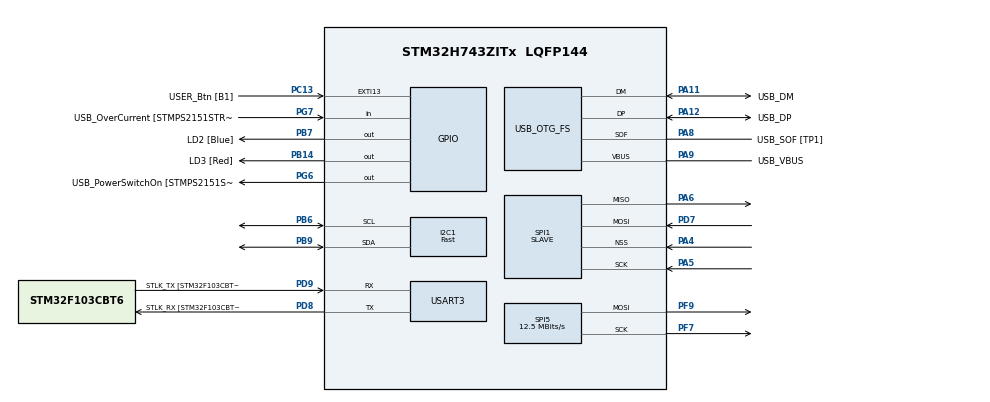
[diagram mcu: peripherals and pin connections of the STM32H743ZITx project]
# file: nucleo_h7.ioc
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FREERTOS.Tasks01=defaultTask,0,128,StartDefaultTask,Default,NULL
I2C1.I2C_Speed_Mode=I2C_Fast
I2C1.Timing=0x009034B6
Mcu.Family=STM32H7
Mcu.Name=STM32H743ZITx
Mcu.Package=LQFP144
NVIC.PriorityGroup=NVIC_PRIORITYGROUP_4
NVIC.SPI1_IRQn=true\:5\:0\:false\:false\:true\:true\:true
NVIC.TIM1_UP_IRQn=true\:0\:0\:false\:false\:true\:false\:false
NVIC.TimeBase=TIM1_UP_IRQn
NVIC.TimeBaseIP=TIM1
PA1.GPIO_Label=RMII_REF_CLK
PA1.Signal=ETH_REF_CLK
PA10.GPIO_Label=USB_ID
PA10.Signal=USB_OTG_FS_ID
PA11.GPIO_Label=USB_DM
PA11.Mode=Device_Only
PA11.Signal=USB_OTG_FS_DM
PA12.GPIO_Label=USB_DP
PA12.Mode=Device_Only
PA12.Signal=USB_OTG_FS_DP
PA13\ (JTMS/SWDIO).GPIO_Label=TMS
PA13\ (JTMS/SWDIO).Mode=Serial_Wire
PA13\ (JTMS/SWDIO).Signal=SYS_JTMS-SWDIO
PA14\ (JTCK/SWCLK).GPIO_Label=TCK
PA14\ (JTCK/SWCLK).Mode=Serial_Wire
PA14\ (JTCK/SWCLK).Signal=SYS_JTCK-SWCLK
PA2.GPIO_Label=RMII_MDIO
PA2.Signal=ETH_MDIO
PA4.GPIO_Speed=GPIO_SPEED_FREQ_VERY_HIGH
PA4.Mode=NSS_Signal_Hard_Input
PA4.Signal=SPI1_NSS
PA5.GPIO_Speed=GPIO_SPEED_FREQ_VERY_HIGH
PA5.Mode=Full_Duplex_Slave
PA5.Signal=SPI1_SCK
PA6.GPIO_Speed=GPIO_SPEED_FREQ_VERY_HIGH
PA6.Mode=Full_Duplex_Slave
PA6.Signal=SPI1_MISO
PA7.GPIO_Label=RMII_CRS_DV
PA7.Signal=ETH_CRS_DV
PA8.GPIO_Label=USB_SOF [TP1]
PA8.Mode=Activate_SOF_FS
PA8.Signal=USB_OTG_FS_SOF
PA9.GPIO_Label=USB_VBUS
PA9.Mode=Activate_VBUS
PA9.Signal=USB_OTG_FS_VBUS
PB13.GPIO_Label=RMII_TXD1
PB13.Signal=ETH_TXD1
PB14.GPIO_Label=LD3 [Red]
PB14.Signal=GPIO_Output
PB3\ (JTDO/TRACESWO).GPIO_Label=SWO
PB3\ (JTDO/TRACESWO).Signal=SYS_JTDO-SWO
PB6.GPIO_FM6=SYSCFG_PMCR_I2C_PB6_FMP
PB6.Mode=I2C
PB6.Signal=I2C1_SCL
PB7.GPIO_Label=LD2 [Blue]
PB7.Signal=GPIO_Output
PB9.GPIO_FM9=SYSCFG_PMCR_I2C_PB9_FMP
PB9.Mode=I2C
PB9.Signal=I2C1_SDA
PC1.GPIO_Label=RMII_MDC
PC1.Signal=ETH_MDC
PC13.GPIO_Label=USER_Btn [B1]
PC13.Signal=GPXTI13
PC14-OSC32_IN\ (OSC32_IN).Mode=LSE-External-Oscillator
PC14-OSC32_IN\ (OSC32_IN).Signal=RCC_OSC32_IN
PC15-OSC32_OUT\ (OSC32_OUT).Mode=LSE-External-Oscillator
PC15-OSC32_OUT\ (OSC32_OUT).Signal=RCC_OSC32_OUT
PC4.GPIO_Label=RMII_RXD0
PC4.Signal=ETH_RXD0
PC5.GPIO_Label=RMII_RXD1
PC5.Signal=ETH_RXD1
PD7.GPIO_Speed=GPIO_SPEED_FREQ_VERY_HIGH
PD7.Mode=Full_Duplex_Slave
PD7.Signal=SPI1_MOSI
PD8.GPIO_Label=STLK_RX [STM32F103CBT6_PA3]
PD8.Mode=Asynchronous
PD8.Signal=USART3_TX
PD9.GPIO_Label=STLK_TX [STM32F103CBT6_PA2]
PD9.Mode=Asynchronous
PD9.Signal=USART3_RX
PF7.Mode=TX_Only_Simplex_Unidirect_Master
PF7.Signal=SPI5_SCK
PF9.Mode=TX_Only_Simplex_Unidirect_Master
PF9.Signal=SPI5_MOSI
PG11.GPIO_Label=RMII_TX_EN
PG11.Signal=ETH_TX_EN
PG13.GPIO_Label=RMII_TXD0
PG13.Signal=ETH_TXD0
PG6.GPIO_Label=USB_PowerSwitchOn [STMPS2151STR_EN]
PG6.Signal=GPIO_Output
PG7.GPIO_Label=USB_OverCurrent [STMPS2151STR_FAULT]
PG7.Signal=GPIO_Input
PH0-OSC_IN\ (PH0).GPIO_Label=MCO
PH0-OSC_IN\ (PH0).Mode=HSE-External-Clock-Source
PH0-OSC_IN\ (PH0).Signal=RCC_OSC_IN
PH1-OSC_OUT\ (PH1).Mode=HSE-External-Clock-Source
PH1-OSC_OUT\ (PH1).Signal=RCC_OSC_OUT
ProjectManager.HeapSize=0x200
ProjectManager.StackSize=0x400
ProjectManager.TargetToolchain=Makefile
RCC.48MHZClocksFreq_Value=24000000
RCC.ADCFreq_Value=4687500
RCC.AHBFreq_Value=216000000
RCC.APB1CLKDivider=RCC_HCLK_DIV4
RCC.APB1Freq_Value=100000000
RCC.APB1TimFreq_Value=108000000
RCC.APB2CLKDivider=RCC_HCLK_DIV2
RCC.APB2Freq_Value=100000000
RCC.APB2TimFreq_Value=216000000
RCC.APB3Freq_Value=100000000
RCC.APB4Freq_Value=100000000
RCC.CortexFreq_Value=400000000
RCC.DIVM1=1
RCC.DIVM2=8
RCC.DIVN1=100
RCC.DIVN2=150
RCC.DIVP2=32
RCC.DIVQ1=4
RCC.HCLKFreq_Value=100000000
RCC.HPRE=RCC_HCLK_DIV4
RCC.HSE_VALUE=8000000
RCC.HSI_VALUE=64000000
RCC.PLLM=25
RCC.PLLMUL=RCC_PLL_MUL9
RCC.PLLN=432
RCC.PLLQ=9
RCC.PLLSourceVirtual=RCC_PLLSOURCE_HSE
RCC.PRESCALERUSB=RCC_USBCLKSOURCE_PLL_DIV1_5
RCC.SPI123CLockSelection=RCC_SPI123CLKSOURCE_PLL2
RCC.SYSCLKFreq_VALUE=400000000
RCC.SYSCLKSource=RCC_SYSCLKSOURCE_PLLCLK
RCC.SYSCLKSourceVirtual=RCC_SYSCLKSOURCE_PLLCLK
RCC.USBCLockSelection=RCC_USBCLKSOURCE_HSI48
RCC.USBFreq_Value=48000000
RCC.VCOOutputFreq_Value=432000000
SPI1.DataSize=SPI_DATASIZE_8BIT
SPI1.Direction=SPI_DIRECTION_2LINES
SPI1.Mode=SPI_MODE_SLAVE
SPI1.VirtualNSS=VM_NSSHARD
SPI1.VirtualType=VM_SLAVE
SPI5.BaudRatePrescaler=SPI_BAUDRATEPRESCALER_8
SPI5.CalculateBaudRate=12.5 MBits/s
SPI5.DataSize=SPI_DATASIZE_8BIT
SPI5.Direction=SPI_DIRECTION_2LINES_TXONLY
SPI5.Mode=SPI_MODE_MASTER
SPI5.VirtualType=VM_MASTER
USART3.VirtualMode-Asynchronous=VM_ASYNC
USB_OTG_FS.VirtualMode=Device_Only
VP_FREERTOS_VS_ENABLE.Mode=Enabled
VP_SYS_VS_tim1.Mode=TIM1
board=NUCLEO-H743ZI

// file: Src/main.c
/* USER CODE BEGIN Header */
/**
  ******************************************************************************
  * @file           : main.c
  * @brief          : Main program body
  ******************************************************************************
  * This notice applies to any and all portions of this file
  * that are not between comment pairs USER CODE BEGIN and
  * USER CODE END. Other portions of this file, whether
  * inserted by the user or by software development tools
  * are owned by their respective copyright owners.
  *
  * Copyright (c) 2019 STMicroelectronics International N.V.
  * All rights reserved.
  *
  * Redistribution and use in source and binary forms, with or without
  * modification, are permitted, provided that the following conditions are met:
  *
  * 1. Redistribution of source code must retain the above copyright notice,
  *    this list of conditions and the following disclaimer.
  * 2. Redistributions in binary form must reproduce the above copyright notice,
  *    this list of conditions and the following disclaimer in the documentation
  *    and/or other materials provided with the distribution.
  * 3. Neither the name of STMicroelectronics nor the names of other
  *    contributors to this software may be used to endorse or promote products
  *    derived from this software without specific written permission.
  * 4. This software, including modifications and/or derivative works of this
  *    software, must execute solely and exclusively on microcontroller or
  *    microprocessor devices manufactured by or for STMicroelectronics.
  * 5. Redistribution and use of this software other than as permitted under
  *    this license is void and will automatically terminate your rights under
  *    this license.
  *
  * THIS SOFTWARE IS PROVIDED BY STMICROELECTRONICS AND CONTRIBUTORS "AS IS"
  * AND ANY EXPRESS, IMPLIED OR STATUTORY WARRANTIES, INCLUDING, BUT NOT
  * LIMITED TO, THE IMPLIED WARRANTIES OF MERCHANTABILITY, FITNESS FOR A
  * PARTICULAR PURPOSE AND NON-INFRINGEMENT OF THIRD PARTY INTELLECTUAL PROPERTY
  * RIGHTS ARE DISCLAIMED TO THE FULLEST EXTENT PERMITTED BY LAW. IN NO EVENT
  * SHALL STMICROELECTRONICS OR CONTRIBUTORS BE LIABLE FOR ANY DIRECT, INDIRECT,
  * INCIDENTAL, SPECIAL, EXEMPLARY, OR CONSEQUENTIAL DAMAGES (INCLUDING, BUT NOT
  * LIMITED TO, PROCUREMENT OF SUBSTITUTE GOODS OR SERVICES; LOSS OF USE, DATA,
  * OR PROFITS; OR BUSINESS INTERRUPTION) HOWEVER CAUSED AND ON ANY THEORY OF
  * LIABILITY, WHETHER IN CONTRACT, STRICT LIABILITY, OR TORT (INCLUDING
  * NEGLIGENCE OR OTHERWISE) ARISING IN ANY WAY OUT OF THE USE OF THIS SOFTWARE,
  * EVEN IF ADVISED OF THE POSSIBILITY OF SUCH DAMAGE.
  *
  ******************************************************************************
  */
/* USER CODE END Header */

#include "main.h"
#include "cmsis_os.h"
#include "i2c.h"
#include "spi.h"
#include "usart.h"
#include "usb_otg.h"
#include "gpio.h"

/* USER CODE BEGIN Includes */
#include "main_task.h"
#include "SEGGER_RTT.h"

/* USER CODE END Includes */

/* USER CODE BEGIN PV */
osThreadId main_task_handle;

/* USER CODE END PV */

void SystemClock_Config(void);
void MX_FREERTOS_Init(void);

int main(void)
{

  /* MCU Configuration--------------------------------------------------------*/

  /* Reset of all peripherals, Initializes the Flash interface and the Systick. */
  HAL_Init();

  /* Configure the system clock */
  SystemClock_Config();

  /* Initialize all configured peripherals */
  MX_GPIO_Init();
  MX_USART3_UART_Init();
  MX_USB_OTG_FS_PCD_Init();
  MX_I2C1_Init();
  MX_SPI1_Init();
  MX_SPI5_Init();
  /* USER CODE BEGIN 2 */
  SEGGER_RTT_printf(0,"error hal state i2c %x\r\n",HAL_I2C_GetState(&hi2c1));
  osThreadDef(main_thread, main_task, osPriorityNormal, 0, 1024);
  main_task_handle = osThreadCreate(osThread(main_thread), NULL);

  /* USER CODE END 2 */

  /* Start scheduler */
  osKernelStart();

  /* We should never get here as control is now taken by the scheduler */

  /* Infinite loop */
  while (1)
  {

  }
}

void SystemClock_Config(void)
{
  RCC_OscInitTypeDef RCC_OscInitStruct = {0};
  RCC_ClkInitTypeDef RCC_ClkInitStruct = {0};
  RCC_PeriphCLKInitTypeDef PeriphClkInitStruct = {0};

  /**Supply configuration update enable
  */
  MODIFY_REG(PWR->CR3, PWR_CR3_SCUEN, 0);
  /**Configure the main internal regulator output voltage
  */
  __HAL_PWR_VOLTAGESCALING_CONFIG(PWR_REGULATOR_VOLTAGE_SCALE1);

  while ((PWR->D3CR & (PWR_D3CR_VOSRDY)) != PWR_D3CR_VOSRDY)
  {

  }
  /**Macro to configure the PLL clock source
  */
  __HAL_RCC_PLL_PLLSOURCE_CONFIG(RCC_PLLSOURCE_HSE);
  /**Initializes the CPU, AHB and APB busses clocks
  */
  RCC_OscInitStruct.OscillatorType = RCC_OSCILLATORTYPE_HSI48|RCC_OSCILLATORTYPE_HSE;
  RCC_OscInitStruct.HSEState = RCC_HSE_BYPASS;
  RCC_OscInitStruct.HSI48State = RCC_HSI48_ON;
  RCC_OscInitStruct.PLL.PLLState = RCC_PLL_ON;
  RCC_OscInitStruct.PLL.PLLSource = RCC_PLLSOURCE_HSE;
  RCC_OscInitStruct.PLL.PLLM = 1;
  RCC_OscInitStruct.PLL.PLLN = 100;
  RCC_OscInitStruct.PLL.PLLP = 2;
  RCC_OscInitStruct.PLL.PLLQ = 4;
  RCC_OscInitStruct.PLL.PLLR = 2;
  RCC_OscInitStruct.PLL.PLLRGE = RCC_PLL1VCIRANGE_3;
  RCC_OscInitStruct.PLL.PLLVCOSEL = RCC_PLL1VCOWIDE;
  RCC_OscInitStruct.PLL.PLLFRACN = 0;
  if (HAL_RCC_OscConfig(&RCC_OscInitStruct) != HAL_OK)
  {
    Error_Handler();
  }
  /**Initializes the CPU, AHB and APB busses clocks
  */
  RCC_ClkInitStruct.ClockType = RCC_CLOCKTYPE_HCLK|RCC_CLOCKTYPE_SYSCLK
                              |RCC_CLOCKTYPE_PCLK1|RCC_CLOCKTYPE_PCLK2
                              |RCC_CLOCKTYPE_D3PCLK1|RCC_CLOCKTYPE_D1PCLK1;
  RCC_ClkInitStruct.SYSCLKSource = RCC_SYSCLKSOURCE_PLLCLK;
  RCC_ClkInitStruct.SYSCLKDivider = RCC_SYSCLK_DIV1;
  RCC_ClkInitStruct.AHBCLKDivider = RCC_HCLK_DIV4;
  RCC_ClkInitStruct.APB3CLKDivider = RCC_APB3_DIV1;
  RCC_ClkInitStruct.APB1CLKDivider = RCC_APB1_DIV1;
  RCC_ClkInitStruct.APB2CLKDivider = RCC_APB2_DIV1;
  RCC_ClkInitStruct.APB4CLKDivider = RCC_APB4_DIV1;

  if (HAL_RCC_ClockConfig(&RCC_ClkInitStruct, FLASH_LATENCY_1) != HAL_OK)
  {
    Error_Handler();
  }
  PeriphClkInitStruct.PeriphClockSelection = RCC_PERIPHCLK_USART3|RCC_PERIPHCLK_SPI5
                              |RCC_PERIPHCLK_SPI1|RCC_PERIPHCLK_I2C1
                              |RCC_PERIPHCLK_USB;
  PeriphClkInitStruct.PLL2.PLL2M = 8;
  PeriphClkInitStruct.PLL2.PLL2N = 150;
  PeriphClkInitStruct.PLL2.PLL2P = 32;
  PeriphClkInitStruct.PLL2.PLL2Q = 2;
  PeriphClkInitStruct.PLL2.PLL2R = 2;
  PeriphClkInitStruct.PLL2.PLL2RGE = RCC_PLL2VCIRANGE_0;
  PeriphClkInitStruct.PLL2.PLL2VCOSEL = RCC_PLL2VCOMEDIUM;
  PeriphClkInitStruct.PLL2.PLL2FRACN = 0;
  PeriphClkInitStruct.Spi123ClockSelection = RCC_SPI123CLKSOURCE_PLL2;
  PeriphClkInitStruct.Spi45ClockSelection = RCC_SPI45CLKSOURCE_D2PCLK1;
  PeriphClkInitStruct.Usart234578ClockSelection = RCC_USART234578CLKSOURCE_D2PCLK1;
  PeriphClkInitStruct.I2c123ClockSelection = RCC_I2C123CLKSOURCE_D2PCLK1;
  PeriphClkInitStruct.UsbClockSelection = RCC_USBCLKSOURCE_HSI48;
  if (HAL_RCCEx_PeriphCLKConfig(&PeriphClkInitStruct) != HAL_OK)
  {
    Error_Handler();
  }
}

void HAL_TIM_PeriodElapsedCallback(TIM_HandleTypeDef *htim)
{
  if (htim->Instance == TIM1) {
    HAL_IncTick();
  }
}

void Error_Handler(void)
{
}

/************************ (C) COPYRIGHT STMicroelectronics *****END OF FILE****/
